# STM32G07x register map
File version: 1.3
CPU: CM0+ r0p0, little endian, no MPU, no FPU, 3 interrupt priority bits
Registers are 32-bit, read-write, reset 0x0 unless marked. A register's access mark holds for its fields unless they carry their own. Offsets are from the block's base; [hi:lo] are bit positions; lines under a group give offsets from that group; {n}, {i} and the like mark numbered series.

## ADC — Analog to Digital Converter instance 1
Base 0x40012400
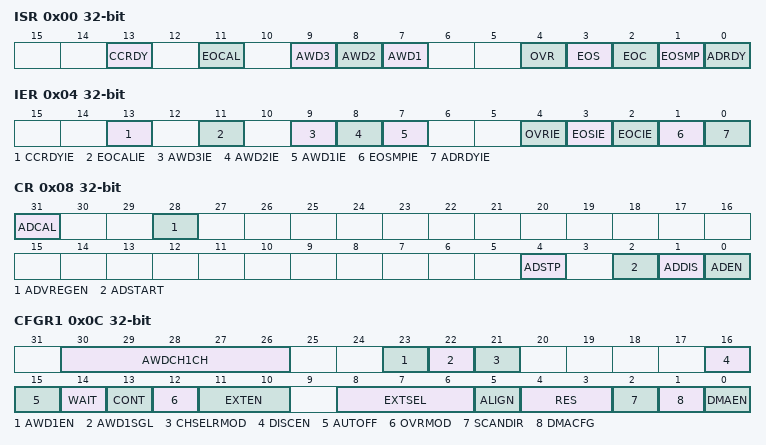
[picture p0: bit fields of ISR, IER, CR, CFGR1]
0x00 ISR — ADC interrupt and status register
  [13] CCRDY — Channel Configuration Ready flag
  [11] EOCAL — End Of Calibration flag
  [9] AWD3 — ADC analog watchdog 3 flag
  [8] AWD2 — ADC analog watchdog 2 flag
  [7] AWD1 — ADC analog watchdog 1 flag
  [4] OVR — ADC group regular overrun flag
  [3] EOS — ADC group regular end of sequence conversions flag
  [2] EOC — ADC group regular end of unitary conversion flag
  [1] EOSMP — ADC group regular end of sampling flag
  [0] ADRDY — ADC ready flag
0x04 IER — ADC interrupt enable register
  [13] CCRDYIE — Channel Configuration Ready Interrupt enable
  [11] EOCALIE — End of calibration interrupt enable
  [9] AWD3IE — ADC analog watchdog 3 interrupt
  [8] AWD2IE — ADC analog watchdog 2 interrupt
  [7] AWD1IE — ADC analog watchdog 1 interrupt
  [4] OVRIE — ADC group regular overrun interrupt
  [3] EOSIE — ADC group regular end of sequence conversions interrupt
  [2] EOCIE — ADC group regular end of unitary conversion interrupt
  [1] EOSMPIE — ADC group regular end of sampling interrupt
  [0] ADRDYIE — ADC ready interrupt
0x08 CR — ADC control register
  [31] ADCAL — ADC calibration
  [28] ADVREGEN — ADC voltage regulator enable
  [4] ADSTP — ADC group regular conversion stop
  [2] ADSTART — ADC group regular conversion start
  [1] ADDIS — ADC disable
  [0] ADEN — ADC enable
0x0C CFGR1 — ADC configuration register 1
  [30:26] AWDCH1CH — ADC analog watchdog 1 monitored channel selection
  [23] AWD1EN — ADC analog watchdog 1 enable on scope ADC group regular
  [22] AWD1SGL — ADC analog watchdog 1 monitoring a single channel or all channels
  [21] CHSELRMOD — Mode selection of the ADC_CHSELR register
  [16] DISCEN — ADC group regular sequencer discontinuous mode
  [15] AUTOFF — Auto-off mode
  [14] WAIT — Wait conversion mode
  [13] CONT — ADC group regular continuous conversion mode
  [12] OVRMOD — ADC group regular overrun configuration
  [11:10] EXTEN — ADC group regular external trigger polarity
  [8:6] EXTSEL — ADC group regular external trigger source
  [5] ALIGN — ADC data alignement
  [4:3] RES — ADC data resolution
  [2] SCANDIR — Scan sequence direction
  [1] DMACFG — ADC DMA transfer configuration
  [0] DMAEN — ADC DMA transfer enable
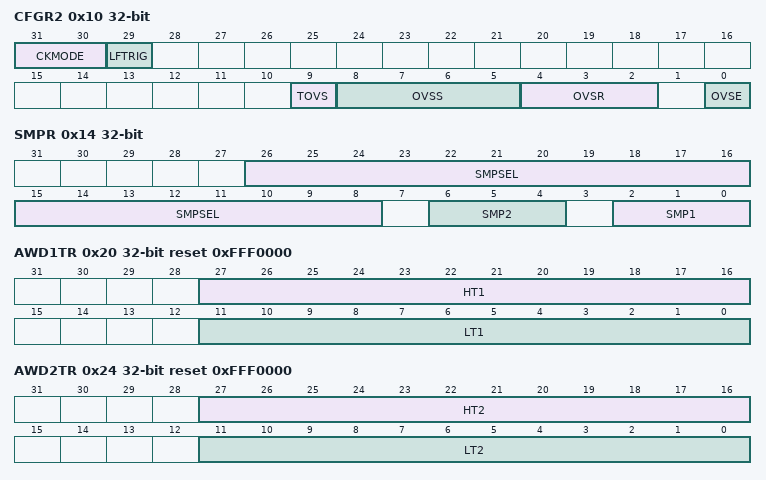
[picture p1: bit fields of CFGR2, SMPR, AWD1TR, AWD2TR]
0x10 CFGR2 — ADC configuration register 2
  [31:30] CKMODE — ADC clock mode
  [29] LFTRIG — Low frequency trigger mode enable
  [9] TOVS — ADC oversampling discontinuous mode (triggered mode) for ADC group regular
  [8:5] OVSS — ADC oversampling shift
  [4:2] OVSR — ADC oversampling ratio
  [0] OVSE — ADC oversampler enable on scope ADC group regular
0x14 SMPR — ADC sampling time register
  [26:8] SMPSEL — Channel sampling time selection
  [6:4] SMP2 — Sampling time selection
  [2:0] SMP1 — Sampling time selection
0x20 AWD1TR reset 0xFFF0000 — watchdog threshold register
  [27:16] HT1 — ADC analog watchdog 1 threshold high
  [11:0] LT1 — ADC analog watchdog 1 threshold low
0x24 AWD2TR reset 0xFFF0000 — watchdog threshold register
  [27:16] HT2 — ADC analog watchdog 2 threshold high
  [11:0] LT2 — ADC analog watchdog 2 threshold low
0x28 CHSELR reset 0xFFF0000 — channel selection register
  [18:0] CHSEL — Channel-x selection
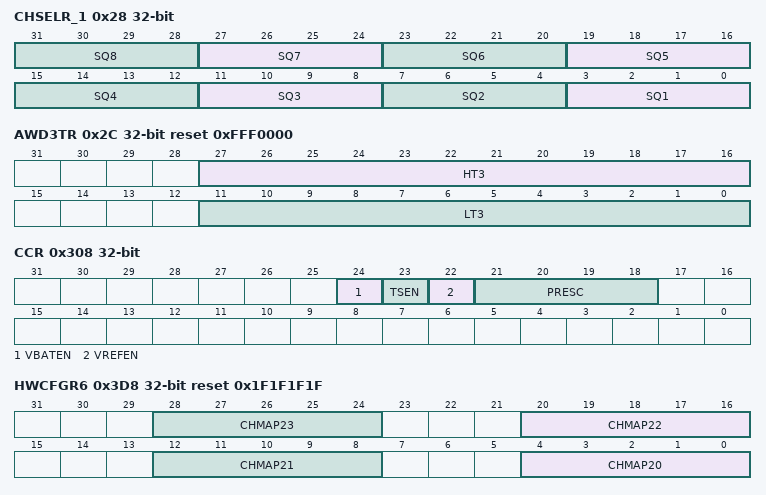
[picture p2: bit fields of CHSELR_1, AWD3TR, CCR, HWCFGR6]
0x28 CHSELR_1 (alternate view of CHSELR) — channel selection register CHSELRMOD = 1 in ADC_CFGR1
  [4n-1:4n-4] SQ{n} (n=1..8) — conversion of the sequence
0x2C AWD3TR reset 0xFFF0000 — watchdog threshold register
  [27:16] HT3 — ADC analog watchdog 3 threshold high
  [11:0] LT3 — ADC analog watchdog 3 threshold high
0x40 DR ro — ADC group regular conversion data register
  [15:0] regularDATA — ADC group regular conversion data
0xA0 AWD2CR — ADC analog watchdog 2 configuration register
  [18:0] AWD2CH — ADC analog watchdog 2 monitored channel selection
0xA4 AWD3CR — ADC analog watchdog 3 configuration register
  [18:0] AWD3CH — ADC analog watchdog 3 monitored channel selection
0xB4 CALFACT — ADC calibration factors register
  [6:0] CALFACT — ADC calibration factor in single-ended mode
0x308 CCR — ADC common control register
  [24] VBATEN — VBAT enable
  [23] TSEN — Temperature sensor enable
  [22] VREFEN — VREFINT enable
  [21:18] PRESC — ADC prescaler
0x3D8 HWCFGR6 reset 0x1F1F1F1F — Hardware Configuration Register
  [8n-156:8n-160] CHMAP{n} (n=20..23) — Input channel mapping
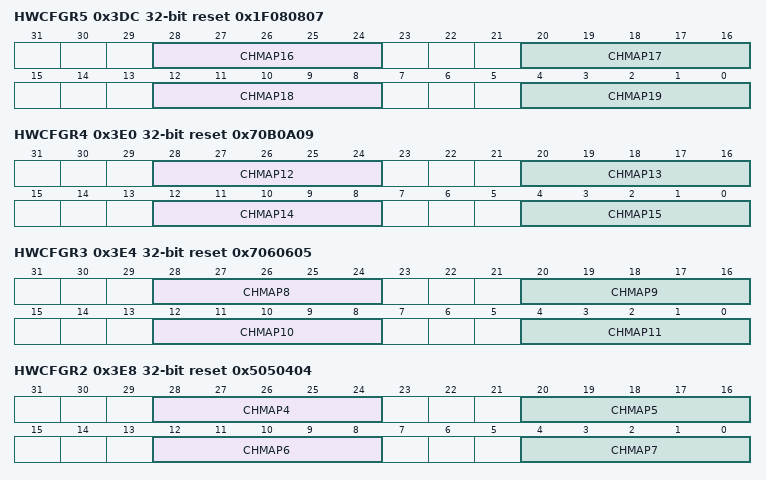
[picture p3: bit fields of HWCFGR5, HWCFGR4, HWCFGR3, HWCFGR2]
0x3DC HWCFGR5 reset 0x1F080807 — Hardware Configuration Register
  [156-8n:152-8n] CHMAP{n} (n=16..19) — Input channel mapping
0x3E0 HWCFGR4 reset 0x70B0A09 — Hardware Configuration Register
  [124-8n:120-8n] CHMAP{n} (n=12..15) — Input channel mapping
0x3E4 HWCFGR3 reset 0x7060605 — Hardware Configuration Register
  [92-8n:88-8n] CHMAP{n} (n=8..11) — Input channel mapping
0x3E8 HWCFGR2 reset 0x5050404 — Hardware Configuration Register
  [60-8n:56-8n] CHMAP{n} (n=4..7) — Input channel mapping
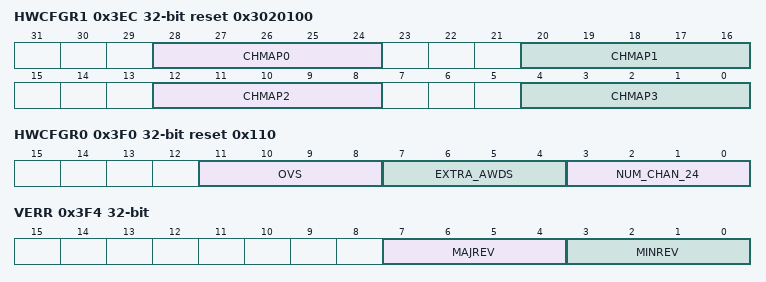
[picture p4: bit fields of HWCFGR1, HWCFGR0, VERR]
0x3EC HWCFGR1 reset 0x3020100 — Hardware Configuration Register
  [28-8n:24-8n] CHMAP{n} (n=0..3) — Input channel mapping
0x3F0 HWCFGR0 ro reset 0x110 — Hardware Configuration Register
  [11:8] OVS — Oversampling
  [7:4] EXTRA_AWDS — Extra analog watchdog
  [3:0] NUM_CHAN_24
0x3F4 VERR ro — EXTI IP Version register
  [7:4] MAJREV — Major Revision number
  [3:0] MINREV — Minor Revision number
0x3F8 IPIDR ro — EXTI Identification register
  [31:0] IPID — IP Identification
0x3FC SIDR ro — EXTI Size ID register
  [31:0] SID — Size Identification
